# GD32W515Px register map
File version: 1.0
CPU: CM33 r0p0, little endian, MPU, FPU, 4 interrupt priority bits
Registers are 32-bit, read-write, reset 0x0 unless marked. A register's access mark holds for its fields unless they carry their own. Offsets are from the block's base; [hi:lo] are bit positions; {n}, {i} and the like mark numbered series.

## TZBMPC2 — Memory protection controller - block based
Base 0x400B0000
Same registers: SEC_TZBMPC2 0x500B0000
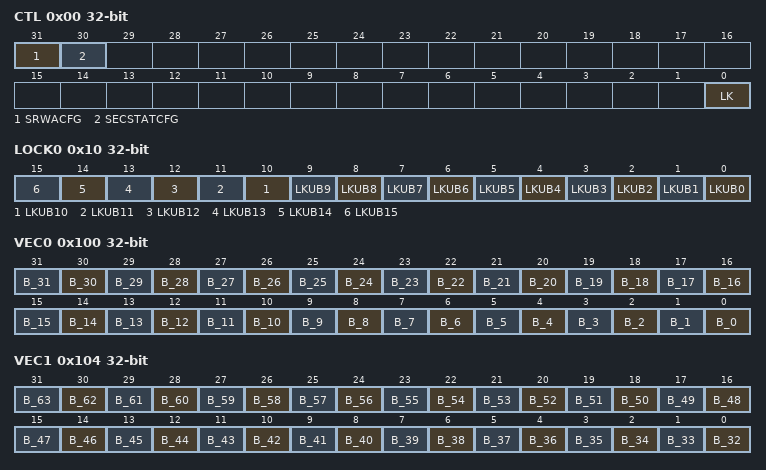
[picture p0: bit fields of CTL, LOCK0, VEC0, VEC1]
0x00 CTL — TZBMPC2 control register
  [31] SRWACFG — secure read/write illegal access disable
  [30] SECSTATCFG — default security state
  [0] LK — TZSPC items lock configuration bit
0x10 LOCK0 — TZBMPC2 lock register 0
  [n] LKUB{n} (n=0..15) — lock/unlock status of secure access mode for the super-blocks {n}
0x100 VEC0 — TZBMPC2 vector register 0
  [n] B_{n} (n=0..31) — blocks {n}
0x104 VEC1 — TZBMPC2 vector register 1
  [n-32] B_{n} (n=32..63) — blocks {n}
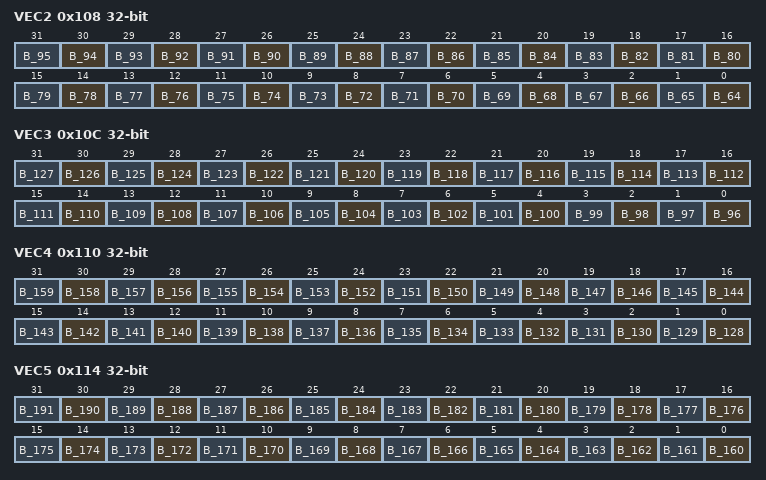
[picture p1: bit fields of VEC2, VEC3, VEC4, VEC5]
0x108 VEC2 — TZBMPC2 vector register 2
  [n-64] B_{n} (n=64..95) — blocks {n}
0x10C VEC3 — TZBMPC2 vector register 3
  [n-96] B_{n} (n=96..127) — blocks {n}
0x110 VEC4 — TZBMPC2 vector register 4
  [n-128] B_{n} (n=128..159) — blocks {n}
0x114 VEC5 — TZBMPC2 vector register 5
  [n-160] B_{n} (n=160..191) — blocks {n}
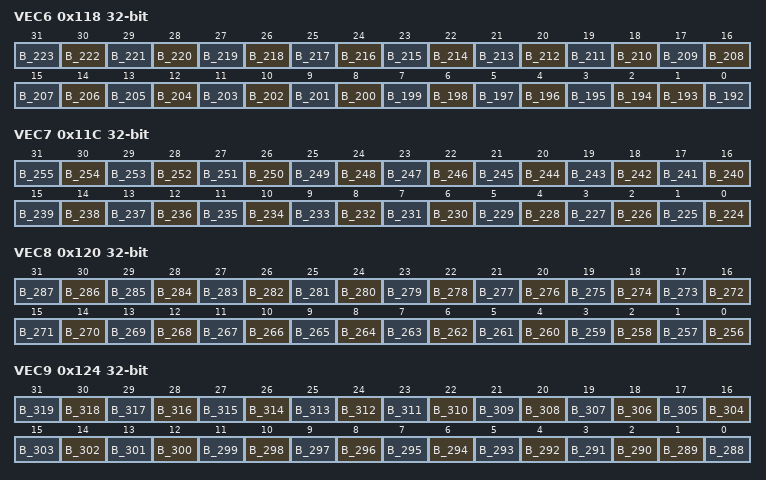
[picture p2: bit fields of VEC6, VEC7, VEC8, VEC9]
0x118 VEC6 — TZBMPC2 vector register 6
  [n-192] B_{n} (n=194..223) — blocks {n}
  [1] B_193 — blocks 93
  [0] B_192 — blocks 192
0x11C VEC7 — TZBMPC2 vector register 7
  [n-224] B_{n} (n=224..255) — blocks {n}
0x120 VEC8 — TZBMPC2 vector register 8
  [n-256] B_{n} (n=256..287) — blocks {n}
0x124 VEC9 — TZBMPC2 vector register 9
  [n-288] B_{n} (n=290..319) — blocks{n}
  [1] B_289 — blocks 289
  [0] B_288 — blocks 288
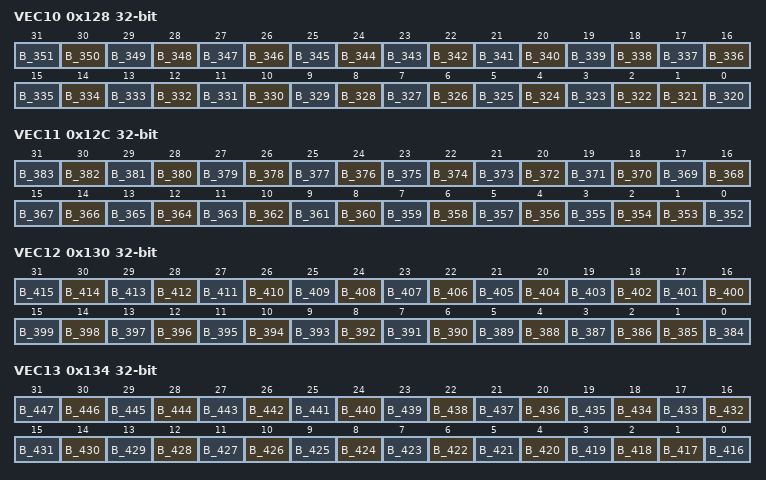
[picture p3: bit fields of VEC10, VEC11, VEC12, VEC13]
0x128 VEC10 — TZBMPC2 vector register 10
  [n-320] B_{n} (n=322..351) — blocks{n}
  [1] B_321 — blocks 321
  [0] B_320 — blocks 320
0x12C VEC11 — TZBMPC2 vector register 11
  [n-352] B_{n} (n=354..383) — blocks{n}
  [1] B_353 — blocks 353
  [0] B_352 — blocks 352
0x130 VEC12 — TZBMPC2 vector register 12
  [n-384] B_{n} (n=386..415) — blocks{n}
  [1] B_385 — blocks 385
  [0] B_384 — blocks 384
0x134 VEC13 — TZBMPC2 vector register 13
  [n-416] B_{n} (n=418..447) — blocks{n}
  [1] B_417 — blocks 417
  [0] B_416 — blocks 416
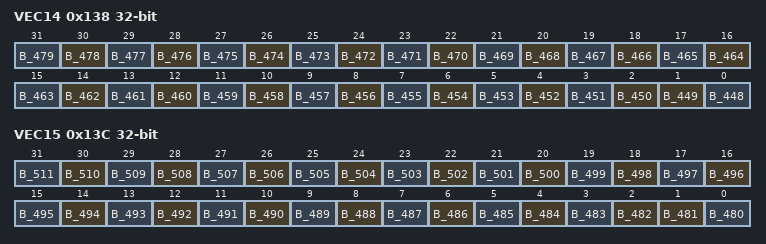
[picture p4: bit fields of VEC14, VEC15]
0x138 VEC14 — TZBMPC2 vector register 14
  [n-448] B_{n} (n=450..479) — blocks{n}
  [1] B_449 — blocks 449
  [0] B_448 — blocks 448
0x13C VEC15 — TZBMPC2 vector register 15
  [n-480] B_{n} (n=482..511) — blocks{n}
  [1] B_481 — blocks 481
  [0] B_480 — blocks 480

## TZBMPC3 — Memory protection controller - block based
Base 0x400B0400
Same registers: SEC_TZBMPC3 0x500B0400
Registers as TZBMPC2 (with TZBMPC2 read as TZBMPC3); these are added or differ:
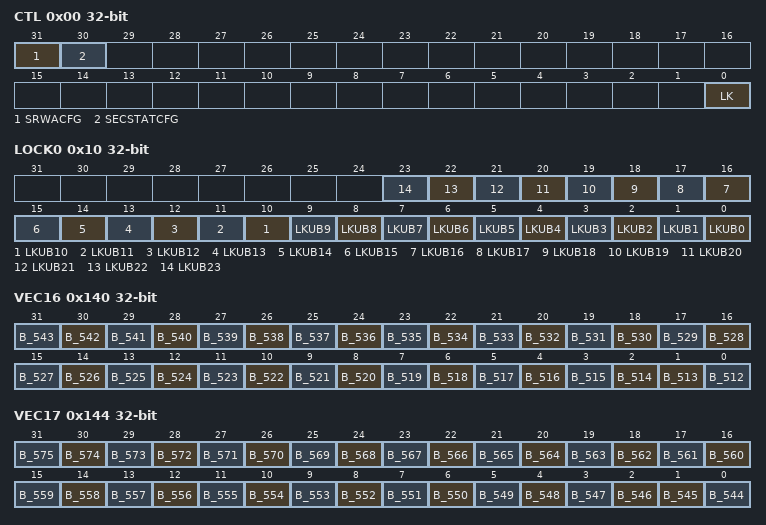
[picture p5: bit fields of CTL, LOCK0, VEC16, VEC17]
0x00 CTL — TZBMPC2 control register
  [31] SRWACFG — secure read/write illegal access disable
  [30] SECSTATCFG — default security state
  [0] LK — TZSPC items lock configuration bit
0x10 LOCK0 — TZBMPC1 lock register0
  [n] LKUB{n} (n=0..23) — lock/unlock status of secure access mode for the super-blocks {n}
0x140 VEC16 — TZBMPC3 vector register 16
  [n-512] B_{n} (n=514..543) — blocks{n}
  [1] B_513 — blocks 513
  [0] B_512 — blocks 512
0x144 VEC17 — TZBMPC3 vector register 17
  [n-544] B_{n} (n=546..575) — blocks{n}
  [1] B_545 — blocks 545
  [0] B_544 — blocks 544
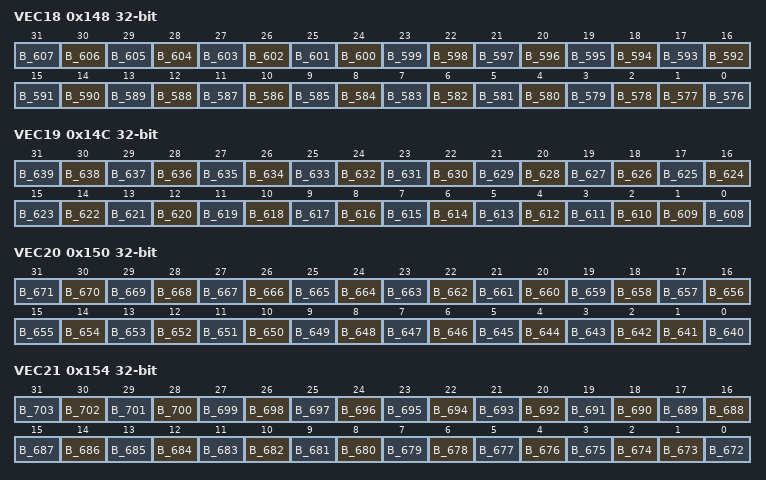
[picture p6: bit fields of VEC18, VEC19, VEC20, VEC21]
0x148 VEC18 — TZBMPC3 vector register 18
  [n-576] B_{n} (n=578..607) — blocks{n}
  [1] B_577 — blocks 577
  [0] B_576 — blocks 576
0x14C VEC19 — TZBMPC3 vector register 19
  [n-608] B_{n} (n=610..639) — blocks{n}
  [1] B_609 — blocks 609
  [0] B_608 — blocks 608
0x150 VEC20 — TZBMPC3 vector register 20
  [n-640] B_{n} (n=642..671) — blocks{n}
  [1] B_641 — blocks 641
  [0] B_640 — blocks 640
0x154 VEC21 — TZBMPC3 vector register 21
  [n-672] B_{n} (n=674..703) — blocks{n}
  [1] B_673 — blocks 673
  [0] B_672 — blocks 672
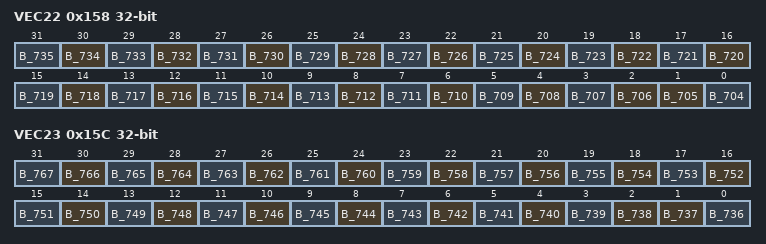
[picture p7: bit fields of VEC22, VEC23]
0x158 VEC22 — TZBMPC3 vector register 22
  [n-704] B_{n} (n=706..735) — blocks{n}
  [1] B_705 — blocks 705
  [0] B_704 — blocks 704
0x15C VEC23 — TZBMPC3 vector register 23
  [n-736] B_{n} (n=738..767) — blocks{n}
  [1] B_737 — blocks 737
  [0] B_736 — blocks 736
